# WKUP_CTRL_MMR0_WKUP_CTRL_MMR_CFG0_43000000h register map
Vendor: Texas Instruments
Registers are 32-bit, read-write, reset 0x0 unless marked. A register's access mark holds for its fields unless they carry their own. Offsets are as the file gives them; [hi:lo] are bit positions; {n}, {i} and the like mark numbered series.

## wkup_ctrl_mmr_CFG0 (part 2 of 3)
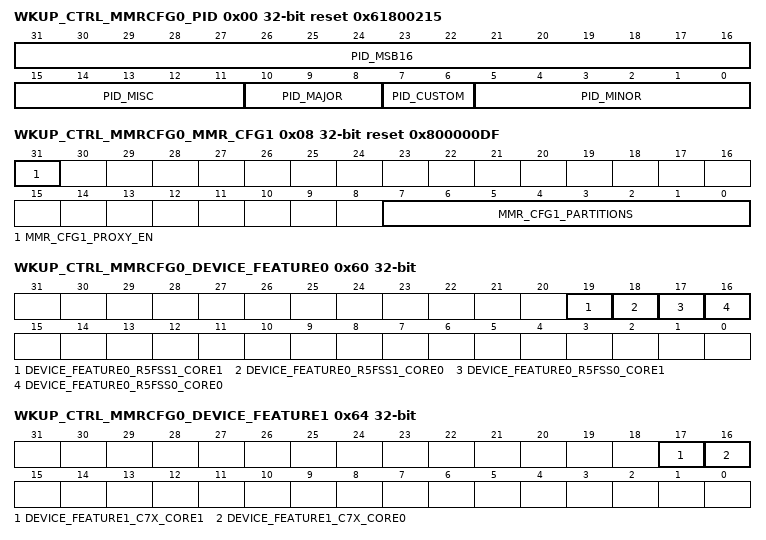
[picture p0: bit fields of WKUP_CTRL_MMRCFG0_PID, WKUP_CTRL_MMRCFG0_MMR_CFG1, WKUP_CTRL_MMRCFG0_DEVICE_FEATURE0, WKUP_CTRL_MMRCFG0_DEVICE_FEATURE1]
0x00 WKUP_CTRL_MMRCFG0_PID ro reset 0x61800215
  [31:16] PID_MSB16 — Reset Source: mod_g_rst_n
  [15:11] PID_MISC — Reset Source: mod_g_rst_n
  [10:8] PID_MAJOR — Reset Source: mod_g_rst_n
  [7:6] PID_CUSTOM — Reset Source: mod_g_rst_n
  [5:0] PID_MINOR — Reset Source: mod_g_rst_n
0x08 WKUP_CTRL_MMRCFG0_MMR_CFG1 ro reset 0x800000DF — Indicates the MMR configuration
  [31] MMR_CFG1_PROXY_EN — Proxy addressing enabled Reset Source: mod_por_rst_n
  [7:0] MMR_CFG1_PARTITIONS — Indicates present partitions Reset Source: mod_por_rst_n
0x44 WKUP_CTRL_MMRCFG0_BOOT_PROGRESS — Used by ROM to mark the progress of the boot operation
  [31:0] BOOT_PROGRESS_PROGRESS — Written by ROM to indicate boot progression. Values and their meaning are determined by the ROM. Reset Source: mod_por_rst_n
0x60 WKUP_CTRL_MMRCFG0_DEVICE_FEATURE0 ro — Indicates enabled Main Domain processing elements on the device
  [19] DEVICE_FEATURE0_R5FSS1_CORE1 — Main R5FSS1 dual/single core supportField values (others are reserved):1'b0 - Single core1'b1 - Dual core Reset Source: mod_por_rst_n
  [18] DEVICE_FEATURE0_R5FSS1_CORE0 — Main R5SS1 avalabilityField values (others are reserved):1'b0 - Cluster not available1'b1 - Cluster available Reset Source: mod_por_rst_n
  [17] DEVICE_FEATURE0_R5FSS0_CORE1 — Main R5FSS0 dual/single core supportField values (others are reserved):1'b0 - Single core1'b1 - Dual core Reset Source: mod_por_rst_n
  [16] DEVICE_FEATURE0_R5FSS0_CORE0 — Main R5SS0 avalabilityField values (others are reserved):1'b0 - Cluster not available1'b1 - Cluster available Reset Source: mod_por_rst_n
0x64 WKUP_CTRL_MMRCFG0_DEVICE_FEATURE1 ro — Indicates enabled Main Domain DSP processing elements on the device
  [17] DEVICE_FEATURE1_C7X_CORE1 — C7x1 AvailabilityField values (others are reserved):1'b0 - Not available1'b1 - Available Reset Source: mod_por_rst_n
  [16] DEVICE_FEATURE1_C7X_CORE0 — C7x0 AvailabilityField values (others are reserved):1'b0 - Not available1'b1 - Available Reset Source: mod_por_rst_n
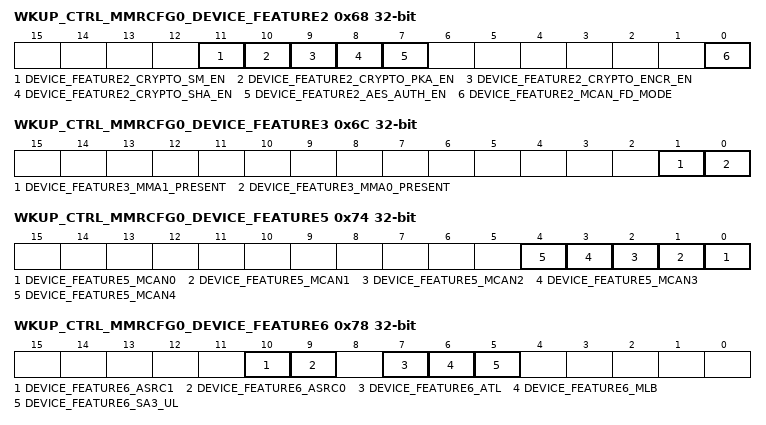
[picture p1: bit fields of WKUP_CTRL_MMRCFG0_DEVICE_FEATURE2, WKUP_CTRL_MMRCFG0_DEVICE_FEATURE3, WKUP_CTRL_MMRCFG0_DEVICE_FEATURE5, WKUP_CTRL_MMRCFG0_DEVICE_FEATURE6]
0x68 WKUP_CTRL_MMRCFG0_DEVICE_FEATURE2 ro — Indicates enabled interface elements on the device
  [11] DEVICE_FEATURE2_CRYPTO_SM_EN — Crypto Module SM2, SM3, SM4 AvailabilityField values (others are reserved):1'b0 - Not available1'b1 - Available Reset Source: mod_por_rst_n
  [10] DEVICE_FEATURE2_CRYPTO_PKA_EN — Crypto Module PKA AvailabilityField values (others are reserved):1'b0 - Not available1'b1 - Available Reset Source: mod_por_rst_n
  [9] DEVICE_FEATURE2_CRYPTO_ENCR_EN — Crypto Module AES/3DES/DBRG AvailabilityField values (others are reserved):1'b0 - Not available1'b1 - Available Reset Source: mod_por_rst_n
  [8] DEVICE_FEATURE2_CRYPTO_SHA_EN — Crypto Module SHA/MD5 AvailabilityField values (others are reserved):1'b0 - Not available1'b1 - Available Reset Source: mod_por_rst_n
  [7] DEVICE_FEATURE2_AES_AUTH_EN — AES authentication availability in FlashSS and SMSField values (others are reserved):1'b0 - Not available1'b1 - Available Reset Source: mod_por_rst_n
  [0] DEVICE_FEATURE2_MCAN_FD_MODE — FD mode availability (applies to all MCAN instances)Field values (others are reserved):1'b0 - Not available1'b1 - Available Reset Source: mod_por_rst_n
0x6C WKUP_CTRL_MMRCFG0_DEVICE_FEATURE3 ro — Indicates enabled processing element features on the device
  [1] DEVICE_FEATURE3_MMA1_PRESENT — C7x1 MMA Feature Availability Reset Source: mod_por_rst_n
  [0] DEVICE_FEATURE3_MMA0_PRESENT — C7x0 MMA Feature Availability Reset Source: mod_por_rst_n
0x74 WKUP_CTRL_MMRCFG0_DEVICE_FEATURE5 ro — Indicates enabled interface elements on the device
  [n] DEVICE_FEATURE5_MCAN{n} (n=0..4) — MCAN{n} AvailabilityField values (others are reserved):1'b0 - Not available1'b1 - Available Reset Source: mod_por_rst_n
0x78 WKUP_CTRL_MMRCFG0_DEVICE_FEATURE6 ro — Indicates enabled interface elements on the device
  [10] DEVICE_FEATURE6_ASRC1 — ASRC1 AvailabilityField values (others are reserved):1'b0 - Not available1'b1 - Available Reset Source: mod_por_rst_n
  [9] DEVICE_FEATURE6_ASRC0 — ASRC0 AvailabilityField values (others are reserved):1'b0 - Not available1'b1 - Available Reset Source: mod_por_rst_n
  [7] DEVICE_FEATURE6_ATL — Audio Tracking Logic AvailabilityField values (others are reserved):1'b0 - Not available1'b1 - Available Reset Source: mod_por_rst_n
  [6] DEVICE_FEATURE6_MLB — Medis Local Bus AvailabilityField values (others are reserved):1'b0 - Not available1'b1 - Available Reset Source: mod_por_rst_n
  [5] DEVICE_FEATURE6_SA3_UL — SA3SS domain security accelerator availabilityField values (others are reserved):1'b0 - Not available1'b1 - Available Reset Source: mod_por_rst_n
0x200 WKUP_CTRL_MMRCFG0_MAC_ID0 — Ethernet MAC address lower 32-bits
  [31:0] MAC_ID0_MACID_LO — 32 lsbs of MAC address Reset Source: mod_g_rst_n
0x204 WKUP_CTRL_MMRCFG0_MAC_ID1 — Ethernet MAC address upper 16-bits
  [15:0] MAC_ID1_MACID_HI — 16 msbs of MAC address Reset Source: mod_g_rst_n
0x220 WKUP_CTRL_MMRCFG0_USB_DEVICE_ID0 reset 0x61650451 — USB device and vendor ID register 0 (ROM Writes)
  [31:0] USB_DEVICE_ID0_ID0 — ROM writes 32-bit Value from Customer OTP to Here Reset Source: mod_g_rst_n
{0x230+4i} WKUP_CTRL_MMRCFG0_GP_SW{i} ro (i=0..2) — Allocated for customer use - Ex. Storage of PID/VID, Model #, Etc.
  [31:0] GP_SW{i}_VAL — general purpose value Reset Source: mod_por_rst_n
0x23C WKUP_CTRL_MMRCFG0_GP_SW3 ro — Allocated for customer use - Ex. Storage of PID/VID, Model #, Etc.
  [3:0] GP_SW3_VAL — general purpose value Reset Source: mod_por_rst_n
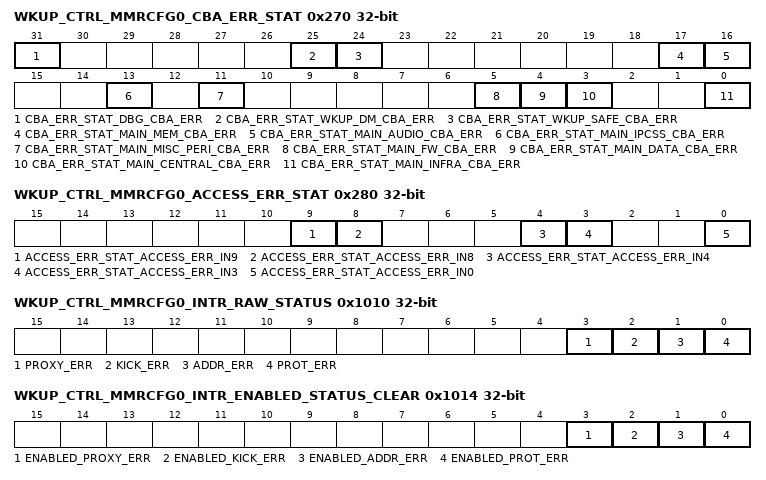
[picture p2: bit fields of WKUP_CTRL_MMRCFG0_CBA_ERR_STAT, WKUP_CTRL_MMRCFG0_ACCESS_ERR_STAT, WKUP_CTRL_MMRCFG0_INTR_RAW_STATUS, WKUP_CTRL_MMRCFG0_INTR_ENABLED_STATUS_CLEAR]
0x270 WKUP_CTRL_MMRCFG0_CBA_ERR_STAT ro — Provides Aggregated, Read Only status of bus address error interrupts reported by CBASS components.. Processors on the SoC read this MMR to determine which CBASS components require service. Actual service of CBASS interrupts must be handled through each CBASS component.
  [31] CBA_ERR_STAT_DBG_CBA_ERR — Access Error from Main Debug CBASSField values (others are reserved):1'b0 - INACTIVE1'b1 - ACTIVE Reset Source: mod_g_rst_n
  [25] CBA_ERR_STAT_WKUP_DM_CBA_ERR — Access Error from Wkup Device Manager CBASSField values (others are reserved):1'b0 - INACTIVE1'b1 - ACTIVE Reset Source: mod_g_rst_n
  [24] CBA_ERR_STAT_WKUP_SAFE_CBA_ERR — Access Error from Wkup Safe CBASSField values (others are reserved):1'b0 - INACTIVE1'b1 - ACTIVE Reset Source: mod_g_rst_n
  [17] CBA_ERR_STAT_MAIN_MEM_CBA_ERR — Access Error from Main MEM CBASS Reset Source: mod_g_rst_n
  [16] CBA_ERR_STAT_MAIN_AUDIO_CBA_ERR — Access Error from Main Audio CBASSField values (others are reserved):1'b0 - INACTIVE1'b1 - ACTIVE Reset Source: mod_g_rst_n
  [13] CBA_ERR_STAT_MAIN_IPCSS_CBA_ERR — Access Error from Main IPCSS CBASSField values (others are reserved):1'b0 - INACTIVE1'b1 - ACTIVE Reset Source: mod_g_rst_n
  [11] CBA_ERR_STAT_MAIN_MISC_PERI_CBA_ERR — Access Errror from Main Misc. Peripheral CBASSField values (others are reserved):1'b0 - INACTIVE1'b1 - ACTIVE Reset Source: mod_g_rst_n
  [5] CBA_ERR_STAT_MAIN_FW_CBA_ERR — Access Error from Main Firewall CBASSField values (others are reserved):1'b0 - INACTIVE1'b1 - ACTIVE Reset Source: mod_g_rst_n
  [4] CBA_ERR_STAT_MAIN_DATA_CBA_ERR — Access Error from Main Data CBASSField values (others are reserved):1'b0 - INACTIVE1'b1 - ACTIVE Reset Source: mod_g_rst_n
  [3] CBA_ERR_STAT_MAIN_CENTRAL_CBA_ERR — Access Error from Main Central CBASSField values (others are reserved):1'b0 - INACTIVE1'b1 - ACTIVE Reset Source: mod_g_rst_n
  [0] CBA_ERR_STAT_MAIN_INFRA_CBA_ERR — Access Error from Main Infrastructure CBASSField values (others are reserved):1'b0 - INACTIVE1'b1 - ACTIVE Reset Source: mod_g_rst_n
0x280 WKUP_CTRL_MMRCFG0_ACCESS_ERR_STAT ro — Provides Aggregated, Read Only status of access error interrupts reported by MMR components.. Processors on the SoC read this MMR to determine which MMR components require service. Actual service of MMR interrupts must be handled through each MMR component.
  [9] ACCESS_ERR_STAT_ACCESS_ERR_IN9 — Access Error Detected in MCU PadCfg MMRField values (others are reserved):1'b0 - INACTIVE1'b1 - ACTIVE Reset Source: mod_por_rst_n
  [8] ACCESS_ERR_STAT_ACCESS_ERR_IN8 — Access Error Detected in MCU Ctrl MMRField values (others are reserved):1'b0 - INACTIVE1'b1 - ACTIVE Reset Source: mod_por_rst_n
  [4] ACCESS_ERR_STAT_ACCESS_ERR_IN4 — Access Error Detected in MAIN PadCfg MMRField values (others are reserved):1'b0 - INACTIVE1'b1 - ACTIVE Reset Source: mod_por_rst_n
  [3] ACCESS_ERR_STAT_ACCESS_ERR_IN3 — Access Error Detected in MAIN Ctrl MMRField values (others are reserved):1'b0 - INACTIVE1'b1 - ACTIVE Reset Source: mod_por_rst_n
  [0] ACCESS_ERR_STAT_ACCESS_ERR_IN0 — Access Error Detected in WKUP Ctrl MMRField values (others are reserved):1'b0 - INACTIVE1'b1 - ACTIVE Reset Source: mod_por_rst_n
{0x1008+0x4000*i} WKUP_CTRL_MMRCFG0_LOCK{i}_KICK0 (i=0..3)
  [31:0] LOCK{i}_KICK0 — - KICK0 component Reset Source: mod_g_rst_n
{0x100C+0x4000*i} WKUP_CTRL_MMRCFG0_LOCK{i}_KICK1 (i=0..3)
  [31:0] LOCK{i}_KICK1 — - KICK1 component Reset Source: mod_g_rst_n
0x1010 WKUP_CTRL_MMRCFG0_INTR_RAW_STATUS access not given
  [3] PROXY_ERR — Proxy0 access violation error. Raw status is read. Write a 1 to set the status. Writing a 0 has no effect. Reset Source: mod_g_rst_n (access R/W1TS)
  [2] KICK_ERR — Kick access violation error. Raw status is read. Write a 1 to set the status. Writing a 0 has no effect. Reset Source: mod_g_rst_n (access R/W1TS)
  [1] ADDR_ERR — Addressing violation error. Raw status is read. Write a 1 to set the status. Writing a 0 has no effect. Reset Source: mod_g_rst_n (access R/W1TS)
  [0] PROT_ERR — Protection violation error. Raw status is read. Write a 1 to set the status. Writing a 0 has no effect. Reset Source: mod_g_rst_n (access R/W1TS)
0x1014 WKUP_CTRL_MMRCFG0_INTR_ENABLED_STATUS_CLEAR access not given
  [3] ENABLED_PROXY_ERR — Proxy0 access violation error. Enabled status is read. Write a 1 to clear the status. Writing a 0 has no effect. Reset Source: mod_g_rst_n (access R/W1TC)
  [2] ENABLED_KICK_ERR — Kick access violation error. Enabled status is read. Write a 1 to clear the status. Writing a 0 has no effect. Reset Source: mod_g_rst_n (access R/W1TC)
  [1] ENABLED_ADDR_ERR — Addressing violation error. Enabled status is read. Write a 1 to clear the status. Writing a 0 has no effect. Reset Source: mod_g_rst_n (access R/W1TC)
  [0] ENABLED_PROT_ERR — Protection violation error. Enabled status is read. Write a 1 to clear the status. Writing a 0 has no effect. Reset Source: mod_g_rst_n (access R/W1TC)
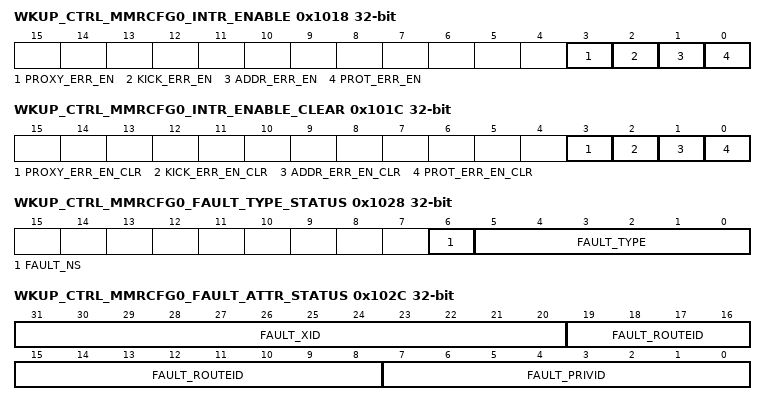
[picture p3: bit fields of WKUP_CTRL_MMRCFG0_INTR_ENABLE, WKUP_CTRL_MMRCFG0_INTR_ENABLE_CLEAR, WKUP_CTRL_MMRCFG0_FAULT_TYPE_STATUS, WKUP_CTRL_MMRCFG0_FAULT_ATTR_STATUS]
0x1018 WKUP_CTRL_MMRCFG0_INTR_ENABLE access not given
  [3] PROXY_ERR_EN — Proxy0 access violation error enable. Write a 1 to set the enable. Writing a 0 has no effect. Reset Source: mod_g_rst_n (access R/W1TS)
  [2] KICK_ERR_EN — Kick access violation error enable. Write a 1 to set the enable. Writing a 0 has no effect. Reset Source: mod_g_rst_n (access R/W1TS)
  [1] ADDR_ERR_EN — Addressing violation error enable. Write a 1 to set the enable. Writing a 0 has no effect. Reset Source: mod_g_rst_n (access R/W1TS)
  [0] PROT_ERR_EN — Protection violation error enable. Write a 1 to set the enable. Writing a 0 has no effect. Reset Source: mod_g_rst_n (access R/W1TS)
0x101C WKUP_CTRL_MMRCFG0_INTR_ENABLE_CLEAR access not given
  [3] PROXY_ERR_EN_CLR — Proxy0 access violation error enable clear. Write a 1 to clear the enable. Writing a 0 has no effect. Reset Source: mod_g_rst_n (access R/W1TC)
  [2] KICK_ERR_EN_CLR — Kick access violation error enable clear. Write a 1 to clear the enable. Writing a 0 has no effect. Reset Source: mod_g_rst_n (access R/W1TC)
  [1] ADDR_ERR_EN_CLR — Addressing violation error enable clear. Write a 1 to clear the enable. Writing a 0 has no effect. Reset Source: mod_g_rst_n (access R/W1TC)
  [0] PROT_ERR_EN_CLR — Protection violation error enable clear. Write a 1 to clear the enable. Writing a 0 has no effect. Reset Source: mod_g_rst_n (access R/W1TC)
0x1024 WKUP_CTRL_MMRCFG0_FAULT_ADDRESS ro
  [31:0] FAULT_ADDR — Fault Address. Reset Source: mod_g_rst_n
0x1028 WKUP_CTRL_MMRCFG0_FAULT_TYPE_STATUS ro
  [6] FAULT_NS — Non-secure access. Reset Source: mod_g_rst_n
  [5:0] FAULT_TYPE — Fault Type 10_0000 = Supervisor read fault - priv = 1 dir = 1 dtype != 1 01_0000 = Supervisor write fault - priv = 1 dir = 0 00_1000 = Supervisor execute fault - priv = 1 dir = 1 dtype = 1 00_0100 = User read fault - priv = 0 dir = 1 dtype = 1 00_0010 = User write fault - priv = 0 dir = 0 00_0001 = User execute fault - priv = 0 dir = 1 dtype = 1 00_0000 = No fault Reset Source: mod_g_rst_n
0x102C WKUP_CTRL_MMRCFG0_FAULT_ATTR_STATUS ro
  [31:20] FAULT_XID — XID. Reset Source: mod_g_rst_n
  [19:8] FAULT_ROUTEID — Route ID. Reset Source: mod_g_rst_n
  [7:0] FAULT_PRIVID — Privilege ID. Reset Source: mod_g_rst_n
0x1030 WKUP_CTRL_MMRCFG0_FAULT_CLEAR wo
  [0] FAULT_CLR — Fault clear. Writing a 1 clears the current fault. Writing a 0 has no effect. Reset Source: mod_g_rst_n
0x1100 WKUP_CTRL_MMRCFG0_CLAIMREG_P0_R0_READONLY ro
  [31:0] CLAIMREG_P0_R0_READONLY — Claim bits for Partition 0 Reset Source: mod_g_rst_n
0x1110 WKUP_CTRL_MMRCFG0_CLAIMREG_P0_R4_READONLY ro
  [31:0] CLAIMREG_P0_R4_READONLY — Claim bits for Partition 0 Reset Source: mod_g_rst_n
0x1114 WKUP_CTRL_MMRCFG0_CLAIMREG_P0_R5_READONLY ro
  [31:0] CLAIMREG_P0_R5_READONLY — Claim bits for Partition 0 Reset Source: mod_g_rst_n
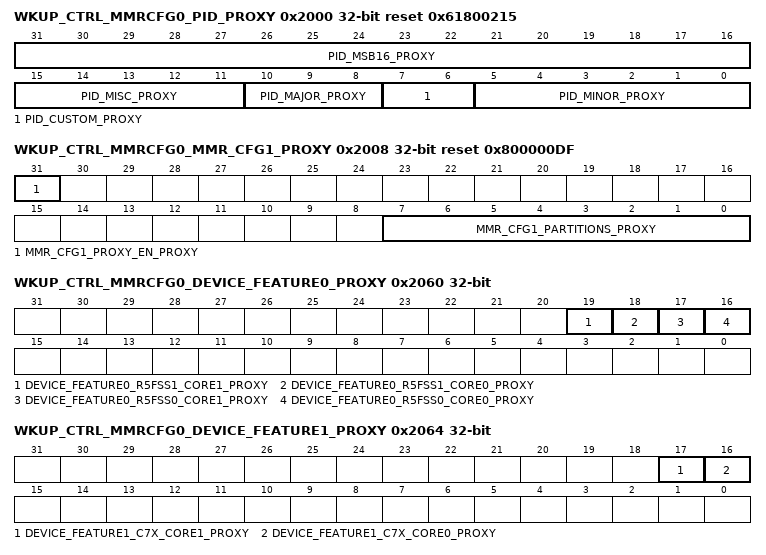
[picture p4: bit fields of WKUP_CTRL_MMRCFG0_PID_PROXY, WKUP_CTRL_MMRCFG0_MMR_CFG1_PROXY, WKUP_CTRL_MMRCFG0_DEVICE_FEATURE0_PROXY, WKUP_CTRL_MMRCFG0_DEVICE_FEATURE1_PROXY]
0x2000 WKUP_CTRL_MMRCFG0_PID_PROXY ro reset 0x61800215
  [31:16] PID_MSB16_PROXY — Reset Source: mod_g_rst_n
  [15:11] PID_MISC_PROXY — Reset Source: mod_g_rst_n
  [10:8] PID_MAJOR_PROXY — Reset Source: mod_g_rst_n
  [7:6] PID_CUSTOM_PROXY — Reset Source: mod_g_rst_n
  [5:0] PID_MINOR_PROXY — Reset Source: mod_g_rst_n
0x2008 WKUP_CTRL_MMRCFG0_MMR_CFG1_PROXY ro reset 0x800000DF — Indicates the MMR configuration
  [31] MMR_CFG1_PROXY_EN_PROXY — Proxy addressing enabled Reset Source: mod_por_rst_n
  [7:0] MMR_CFG1_PARTITIONS_PROXY — Indicates present partitions Reset Source: mod_por_rst_n
0x2044 WKUP_CTRL_MMRCFG0_BOOT_PROGRESS_PROXY — Used by ROM to mark the progress of the boot operation
  [31:0] BOOT_PROGRESS_PROGRESS_PROXY — Written by ROM to indicate boot progression. Values and their meaning are determined by the ROM. Reset Source: mod_por_rst_n
0x2060 WKUP_CTRL_MMRCFG0_DEVICE_FEATURE0_PROXY ro — Indicates enabled Main Domain processing elements on the device
  [19] DEVICE_FEATURE0_R5FSS1_CORE1_PROXY — Main R5FSS1 dual/single core supportField values (others are reserved):1'b0 - Single core1'b1 - Dual core Reset Source: mod_por_rst_n
  [18] DEVICE_FEATURE0_R5FSS1_CORE0_PROXY — Main R5SS1 avalabilityField values (others are reserved):1'b0 - Cluster not available1'b1 - Cluster available Reset Source: mod_por_rst_n
  [17] DEVICE_FEATURE0_R5FSS0_CORE1_PROXY — Main R5FSS0 dual/single core supportField values (others are reserved):1'b0 - Single core1'b1 - Dual core Reset Source: mod_por_rst_n
  [16] DEVICE_FEATURE0_R5FSS0_CORE0_PROXY — Main R5SS0 avalabilityField values (others are reserved):1'b0 - Cluster not available1'b1 - Cluster available Reset Source: mod_por_rst_n
0x2064 WKUP_CTRL_MMRCFG0_DEVICE_FEATURE1_PROXY ro — Indicates enabled Main Domain DSP processing elements on the device
  [17] DEVICE_FEATURE1_C7X_CORE1_PROXY — C7x1 AvailabilityField values (others are reserved):1'b0 - Not available1'b1 - Available Reset Source: mod_por_rst_n
  [16] DEVICE_FEATURE1_C7X_CORE0_PROXY — C7x0 AvailabilityField values (others are reserved):1'b0 - Not available1'b1 - Available Reset Source: mod_por_rst_n
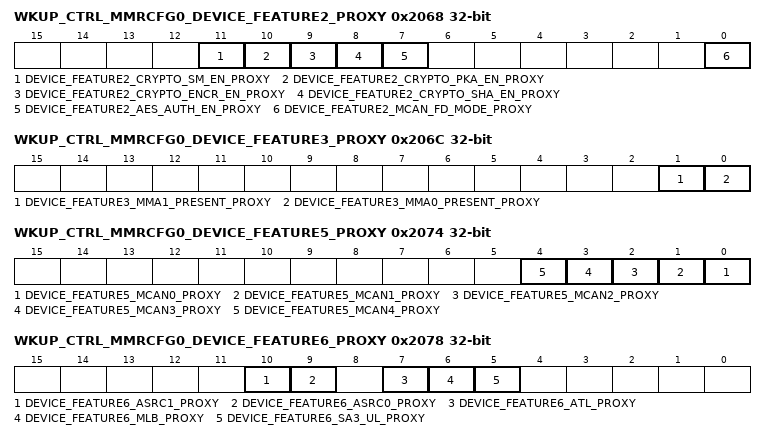
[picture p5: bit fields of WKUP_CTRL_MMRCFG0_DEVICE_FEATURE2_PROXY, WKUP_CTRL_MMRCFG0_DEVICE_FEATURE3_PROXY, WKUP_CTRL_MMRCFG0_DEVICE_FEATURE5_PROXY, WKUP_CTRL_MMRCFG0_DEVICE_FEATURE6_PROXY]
0x2068 WKUP_CTRL_MMRCFG0_DEVICE_FEATURE2_PROXY ro — Indicates enabled interface elements on the device
  [11] DEVICE_FEATURE2_CRYPTO_SM_EN_PROXY — Crypto Module SM2, SM3, SM4 AvailabilityField values (others are reserved):1'b0 - Not available1'b1 - Available Reset Source: mod_por_rst_n
  [10] DEVICE_FEATURE2_CRYPTO_PKA_EN_PROXY — Crypto Module PKA AvailabilityField values (others are reserved):1'b0 - Not available1'b1 - Available Reset Source: mod_por_rst_n
  [9] DEVICE_FEATURE2_CRYPTO_ENCR_EN_PROXY — Crypto Module AES/3DES/DBRG AvailabilityField values (others are reserved):1'b0 - Not available1'b1 - Available Reset Source: mod_por_rst_n
  [8] DEVICE_FEATURE2_CRYPTO_SHA_EN_PROXY — Crypto Module SHA/MD5 AvailabilityField values (others are reserved):1'b0 - Not available1'b1 - Available Reset Source: mod_por_rst_n
  [7] DEVICE_FEATURE2_AES_AUTH_EN_PROXY — AES authentication availability in FlashSS and SMSField values (others are reserved):1'b0 - Not available1'b1 - Available Reset Source: mod_por_rst_n
  [0] DEVICE_FEATURE2_MCAN_FD_MODE_PROXY — FD mode availability (applies to all MCAN instances)Field values (others are reserved):1'b0 - Not available1'b1 - Available Reset Source: mod_por_rst_n
0x206C WKUP_CTRL_MMRCFG0_DEVICE_FEATURE3_PROXY ro — Indicates enabled processing element features on the device
  [1] DEVICE_FEATURE3_MMA1_PRESENT_PROXY — C7x1 MMA Feature Availability Reset Source: mod_por_rst_n
  [0] DEVICE_FEATURE3_MMA0_PRESENT_PROXY — C7x0 MMA Feature Availability Reset Source: mod_por_rst_n
0x2074 WKUP_CTRL_MMRCFG0_DEVICE_FEATURE5_PROXY ro — Indicates enabled interface elements on the device
  [n] DEVICE_FEATURE5_MCAN{n}_PROXY (n=0..4) — MCAN{n} AvailabilityField values (others are reserved):1'b0 - Not available1'b1 - Available Reset Source: mod_por_rst_n
0x2078 WKUP_CTRL_MMRCFG0_DEVICE_FEATURE6_PROXY ro — Indicates enabled interface elements on the device
  [10] DEVICE_FEATURE6_ASRC1_PROXY — ASRC1 AvailabilityField values (others are reserved):1'b0 - Not available1'b1 - Available Reset Source: mod_por_rst_n
  [9] DEVICE_FEATURE6_ASRC0_PROXY — ASRC0 AvailabilityField values (others are reserved):1'b0 - Not available1'b1 - Available Reset Source: mod_por_rst_n
  [7] DEVICE_FEATURE6_ATL_PROXY — Audio Tracking Logic AvailabilityField values (others are reserved):1'b0 - Not available1'b1 - Available Reset Source: mod_por_rst_n
  [6] DEVICE_FEATURE6_MLB_PROXY — Medis Local Bus AvailabilityField values (others are reserved):1'b0 - Not available1'b1 - Available Reset Source: mod_por_rst_n
  [5] DEVICE_FEATURE6_SA3_UL_PROXY — SA3SS domain security accelerator availabilityField values (others are reserved):1'b0 - Not available1'b1 - Available Reset Source: mod_por_rst_n
0x2200 WKUP_CTRL_MMRCFG0_MAC_ID0_PROXY — Ethernet MAC address lower 32-bits
  [31:0] MAC_ID0_MACID_LO_PROXY — 32 lsbs of MAC address Reset Source: mod_g_rst_n
0x2204 WKUP_CTRL_MMRCFG0_MAC_ID1_PROXY — Ethernet MAC address upper 16-bits
  [15:0] MAC_ID1_MACID_HI_PROXY — 16 msbs of MAC address Reset Source: mod_g_rst_n
0x2220 WKUP_CTRL_MMRCFG0_USB_DEVICE_ID0_PROXY reset 0x61650451 — USB device and vendor ID register 0 (ROM Writes)
  [31:0] USB_DEVICE_ID0_ID0_PROXY — ROM writes 32-bit Value from Customer OTP to Here Reset Source: mod_g_rst_n
{0x2230+4i} WKUP_CTRL_MMRCFG0_GP_SW{i}_PROXY ro (i=0..2) — Allocated for customer use - Ex. Storage of PID/VID, Model #, Etc.
  [31:0] GP_SW{i}_VAL_PROXY — general purpose value Reset Source: mod_por_rst_n
0x223C WKUP_CTRL_MMRCFG0_GP_SW3_PROXY ro — Allocated for customer use - Ex. Storage of PID/VID, Model #, Etc.
  [3:0] GP_SW3_VAL_PROXY — general purpose value Reset Source: mod_por_rst_n
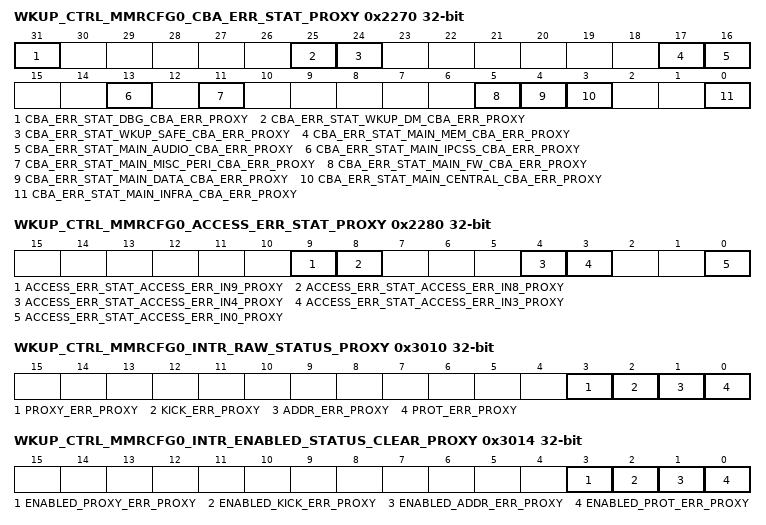
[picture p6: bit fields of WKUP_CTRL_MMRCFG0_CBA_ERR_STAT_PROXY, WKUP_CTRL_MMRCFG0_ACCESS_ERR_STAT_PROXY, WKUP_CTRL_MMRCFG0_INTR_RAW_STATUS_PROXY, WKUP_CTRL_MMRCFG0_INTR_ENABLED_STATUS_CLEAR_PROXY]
0x2270 WKUP_CTRL_MMRCFG0_CBA_ERR_STAT_PROXY ro — Provides Aggregated, Read Only status of bus address error interrupts reported by CBASS components.. Processors on the SoC read this MMR to determine which CBASS components require service. Actual service of CBASS interrupts must be handled through each CBASS component.
  [31] CBA_ERR_STAT_DBG_CBA_ERR_PROXY — Access Error from Main Debug CBASSField values (others are reserved):1'b0 - INACTIVE1'b1 - ACTIVE Reset Source: mod_g_rst_n
  [25] CBA_ERR_STAT_WKUP_DM_CBA_ERR_PROXY — Access Error from Wkup Device Manager CBASSField values (others are reserved):1'b0 - INACTIVE1'b1 - ACTIVE Reset Source: mod_g_rst_n
  [24] CBA_ERR_STAT_WKUP_SAFE_CBA_ERR_PROXY — Access Error from Wkup Safe CBASSField values (others are reserved):1'b0 - INACTIVE1'b1 - ACTIVE Reset Source: mod_g_rst_n
  [17] CBA_ERR_STAT_MAIN_MEM_CBA_ERR_PROXY — Access Error from Main MEM CBASS Reset Source: mod_g_rst_n
  [16] CBA_ERR_STAT_MAIN_AUDIO_CBA_ERR_PROXY — Access Error from Main Audio CBASSField values (others are reserved):1'b0 - INACTIVE1'b1 - ACTIVE Reset Source: mod_g_rst_n
  [13] CBA_ERR_STAT_MAIN_IPCSS_CBA_ERR_PROXY — Access Error from Main IPCSS CBASSField values (others are reserved):1'b0 - INACTIVE1'b1 - ACTIVE Reset Source: mod_g_rst_n
  [11] CBA_ERR_STAT_MAIN_MISC_PERI_CBA_ERR_PROXY — Access Errror from Main Misc. Peripheral CBASSField values (others are reserved):1'b0 - INACTIVE1'b1 - ACTIVE Reset Source: mod_g_rst_n
  [5] CBA_ERR_STAT_MAIN_FW_CBA_ERR_PROXY — Access Error from Main Firewall CBASSField values (others are reserved):1'b0 - INACTIVE1'b1 - ACTIVE Reset Source: mod_g_rst_n
  [4] CBA_ERR_STAT_MAIN_DATA_CBA_ERR_PROXY — Access Error from Main Data CBASSField values (others are reserved):1'b0 - INACTIVE1'b1 - ACTIVE Reset Source: mod_g_rst_n
  [3] CBA_ERR_STAT_MAIN_CENTRAL_CBA_ERR_PROXY — Access Error from Main Central CBASSField values (others are reserved):1'b0 - INACTIVE1'b1 - ACTIVE Reset Source: mod_g_rst_n
  [0] CBA_ERR_STAT_MAIN_INFRA_CBA_ERR_PROXY — Access Error from Main Infrastructure CBASSField values (others are reserved):1'b0 - INACTIVE1'b1 - ACTIVE Reset Source: mod_g_rst_n
0x2280 WKUP_CTRL_MMRCFG0_ACCESS_ERR_STAT_PROXY ro — Provides Aggregated, Read Only status of access error interrupts reported by MMR components.. Processors on the SoC read this MMR to determine which MMR components require service. Actual service of MMR interrupts must be handled through each MMR component.
  [9] ACCESS_ERR_STAT_ACCESS_ERR_IN9_PROXY — Access Error Detected in MCU PadCfg MMRField values (others are reserved):1'b0 - INACTIVE1'b1 - ACTIVE Reset Source: mod_por_rst_n
  [8] ACCESS_ERR_STAT_ACCESS_ERR_IN8_PROXY — Access Error Detected in MCU Ctrl MMRField values (others are reserved):1'b0 - INACTIVE1'b1 - ACTIVE Reset Source: mod_por_rst_n
  [4] ACCESS_ERR_STAT_ACCESS_ERR_IN4_PROXY — Access Error Detected in MAIN PadCfg MMRField values (others are reserved):1'b0 - INACTIVE1'b1 - ACTIVE Reset Source: mod_por_rst_n
  [3] ACCESS_ERR_STAT_ACCESS_ERR_IN3_PROXY — Access Error Detected in MAIN Ctrl MMRField values (others are reserved):1'b0 - INACTIVE1'b1 - ACTIVE Reset Source: mod_por_rst_n
  [0] ACCESS_ERR_STAT_ACCESS_ERR_IN0_PROXY — Access Error Detected in WKUP Ctrl MMRField values (others are reserved):1'b0 - INACTIVE1'b1 - ACTIVE Reset Source: mod_por_rst_n
{0x3008+0x4000*i} WKUP_CTRL_MMRCFG0_LOCK{i}_KICK0_PROXY (i=0..3)
  [31:0] LOCK{i}_KICK0_PROXY — - KICK0 component Reset Source: mod_g_rst_n
{0x300C+0x4000*i} WKUP_CTRL_MMRCFG0_LOCK{i}_KICK1_PROXY (i=0..3)
  [31:0] LOCK{i}_KICK1_PROXY — - KICK1 component Reset Source: mod_g_rst_n
0x3010 WKUP_CTRL_MMRCFG0_INTR_RAW_STATUS_PROXY access not given
  [3] PROXY_ERR_PROXY — Proxy0 access violation error. Raw status is read. Write a 1 to set the status. Writing a 0 has no effect. Reset Source: mod_g_rst_n (access R/W1TS)
  [2] KICK_ERR_PROXY — Kick access violation error. Raw status is read. Write a 1 to set the status. Writing a 0 has no effect. Reset Source: mod_g_rst_n (access R/W1TS)
  [1] ADDR_ERR_PROXY — Addressing violation error. Raw status is read. Write a 1 to set the status. Writing a 0 has no effect. Reset Source: mod_g_rst_n (access R/W1TS)
  [0] PROT_ERR_PROXY — Protection violation error. Raw status is read. Write a 1 to set the status. Writing a 0 has no effect. Reset Source: mod_g_rst_n (access R/W1TS)
0x3014 WKUP_CTRL_MMRCFG0_INTR_ENABLED_STATUS_CLEAR_PROXY access not given
  [3] ENABLED_PROXY_ERR_PROXY — Proxy0 access violation error. Enabled status is read. Write a 1 to clear the status. Writing a 0 has no effect. Reset Source: mod_g_rst_n (access R/W1TC)
  [2] ENABLED_KICK_ERR_PROXY — Kick access violation error. Enabled status is read. Write a 1 to clear the status. Writing a 0 has no effect. Reset Source: mod_g_rst_n (access R/W1TC)
  [1] ENABLED_ADDR_ERR_PROXY — Addressing violation error. Enabled status is read. Write a 1 to clear the status. Writing a 0 has no effect. Reset Source: mod_g_rst_n (access R/W1TC)
  [0] ENABLED_PROT_ERR_PROXY — Protection violation error. Enabled status is read. Write a 1 to clear the status. Writing a 0 has no effect. Reset Source: mod_g_rst_n (access R/W1TC)
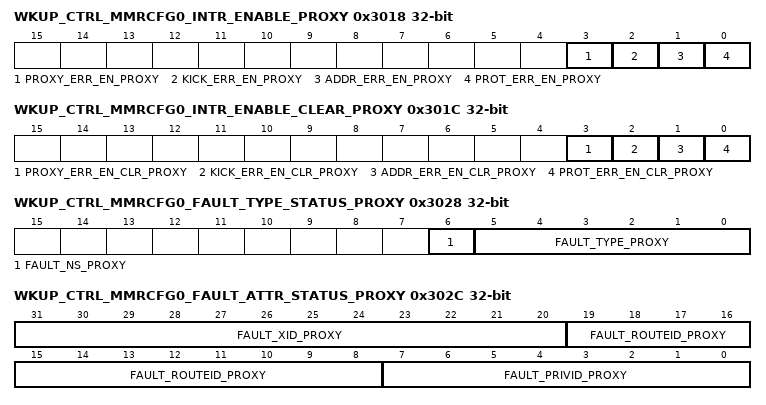
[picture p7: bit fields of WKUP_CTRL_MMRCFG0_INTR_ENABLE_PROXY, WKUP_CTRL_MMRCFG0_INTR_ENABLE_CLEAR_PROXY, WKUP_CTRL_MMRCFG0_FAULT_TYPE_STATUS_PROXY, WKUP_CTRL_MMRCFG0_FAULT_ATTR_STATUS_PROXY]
0x3018 WKUP_CTRL_MMRCFG0_INTR_ENABLE_PROXY access not given
  [3] PROXY_ERR_EN_PROXY — Proxy0 access violation error enable. Write a 1 to set the enable. Writing a 0 has no effect. Reset Source: mod_g_rst_n (access R/W1TS)
  [2] KICK_ERR_EN_PROXY — Kick access violation error enable. Write a 1 to set the enable. Writing a 0 has no effect. Reset Source: mod_g_rst_n (access R/W1TS)
  [1] ADDR_ERR_EN_PROXY — Addressing violation error enable. Write a 1 to set the enable. Writing a 0 has no effect. Reset Source: mod_g_rst_n (access R/W1TS)
  [0] PROT_ERR_EN_PROXY — Protection violation error enable. Write a 1 to set the enable. Writing a 0 has no effect. Reset Source: mod_g_rst_n (access R/W1TS)
0x301C WKUP_CTRL_MMRCFG0_INTR_ENABLE_CLEAR_PROXY access not given
  [3] PROXY_ERR_EN_CLR_PROXY — Proxy0 access violation error enable clear. Write a 1 to clear the enable. Writing a 0 has no effect. Reset Source: mod_g_rst_n (access R/W1TC)
  [2] KICK_ERR_EN_CLR_PROXY — Kick access violation error enable clear. Write a 1 to clear the enable. Writing a 0 has no effect. Reset Source: mod_g_rst_n (access R/W1TC)
  [1] ADDR_ERR_EN_CLR_PROXY — Addressing violation error enable clear. Write a 1 to clear the enable. Writing a 0 has no effect. Reset Source: mod_g_rst_n (access R/W1TC)
  [0] PROT_ERR_EN_CLR_PROXY — Protection violation error enable clear. Write a 1 to clear the enable. Writing a 0 has no effect. Reset Source: mod_g_rst_n (access R/W1TC)
0x3024 WKUP_CTRL_MMRCFG0_FAULT_ADDRESS_PROXY ro
  [31:0] FAULT_ADDR_PROXY — Fault Address. Reset Source: mod_g_rst_n
0x3028 WKUP_CTRL_MMRCFG0_FAULT_TYPE_STATUS_PROXY ro
  [6] FAULT_NS_PROXY — Non-secure access. Reset Source: mod_g_rst_n
  [5:0] FAULT_TYPE_PROXY — Fault Type 10_0000 = Supervisor read fault - priv = 1 dir = 1 dtype != 1 01_0000 = Supervisor write fault - priv = 1 dir = 0 00_1000 = Supervisor execute fault - priv = 1 dir = 1 dtype = 1 00_0100 = User read fault - priv = 0 dir = 1 dtype = 1 00_0010 = User write fault - priv = 0 dir = 0 00_0001 = User execute fault - priv = 0 dir = 1 dtype = 1 00_0000 = No fault Reset Source: mod_g_rst_n
0x302C WKUP_CTRL_MMRCFG0_FAULT_ATTR_STATUS_PROXY ro
  [31:20] FAULT_XID_PROXY — XID. Reset Source: mod_g_rst_n
  [19:8] FAULT_ROUTEID_PROXY — Route ID. Reset Source: mod_g_rst_n
  [7:0] FAULT_PRIVID_PROXY — Privilege ID. Reset Source: mod_g_rst_n
0x3030 WKUP_CTRL_MMRCFG0_FAULT_CLEAR_PROXY wo
  [0] FAULT_CLR_PROXY — Fault clear. Writing a 1 clears the current fault. Writing a 0 has no effect. Reset Source: mod_g_rst_n
{0x3100+4i} WKUP_CTRL_MMRCFG0_CLAIMREG_P0_R{i} (i=0..6)
  [31:0] CLAIMREG_P0_R{i} — Claim bits for Partition 0 Reset Source: mod_g_rst_n
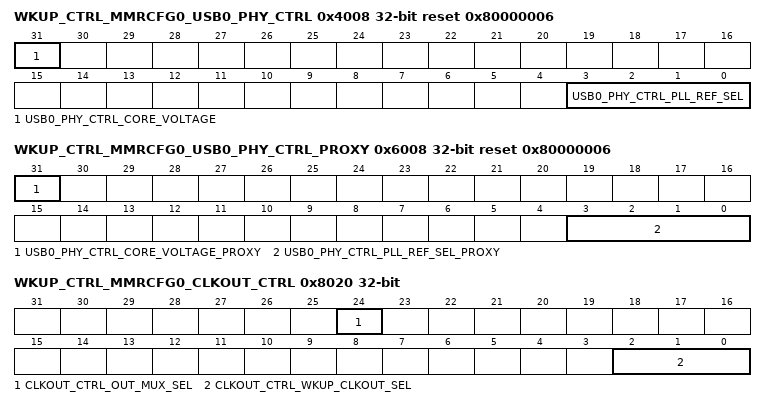
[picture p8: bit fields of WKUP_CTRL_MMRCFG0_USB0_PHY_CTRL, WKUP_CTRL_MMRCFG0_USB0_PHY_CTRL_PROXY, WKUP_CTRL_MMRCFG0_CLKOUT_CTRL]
0x4008 WKUP_CTRL_MMRCFG0_USB0_PHY_CTRL reset 0x80000006 — Configures the USB0 Phy operation
  [31] USB0_PHY_CTRL_CORE_VOLTAGE — Selects the USB PHY Core Voltage Option: 0.85V or 0.75/0.80VField values (others are reserved):1'b0 - V_0P851'b1 - V_0P75_0P80 Reset Source: mod_g_rst_n
  [3:0] USB0_PHY_CTRL_PLL_REF_SEL — Indicates the frequency of the REF_CLOCK input used by the USB PLL. This value should be set to match the frequency of the USB0 input clock, as selected by the USB0_CLKSEL registerField values (others are reserved):4'b0000 - MHZ_9P64'b0001 - MHZ_104'b0010 - MHZ_124'b0011 - MHZ_19P24'b0100 - MHZ_204'b0101 - MHZ_244'b0110 - MHZ_254'b0111 - MHZ_264'b1000 - MHZ_38P44'b1001 - MHZ_404'b1010 - MHZ_484'b1011 - MHZ_504'b1100 - MHZ_52 Reset Source: mod_g_rst_n
0x41B4 WKUP_CTRL_MMRCFG0_SDIO0_CTRL — Controls drive strength of MMC0 SDIO mode pins
  [4:0] SDIO0_CTRL_DRV_STR — Selects the SDIO pin drive strength. The default value trims the buffers for ~40 ohms. For options other than the Reset/Default 40 ohm, the register value should be modified as follows: 40 ohms - Default Value 33 ohms - Default Value + 5 50 ohms - Default Value -5 66 ohms - Default Value -10Note: Values other than the reset value may invalidate the datasheet timing parameters and therefore should not be used. Reset Source: mod_por_rst_n
0x4204 WKUP_CTRL_MMRCFG0_WKUP_TIMER1_CTRL — Controls TIMER1 operation
  [8] WKUP_TIMER1_CTRL_CASCADE_EN — Enables cascading of TIMER1 to TIMER0Field values (others are reserved):1'b0 - CASCADE_DISABLED1'b1 - CASCADE_ENABLED Reset Source: sys_por_rst_n
0x42E0 WKUP_CTRL_MMRCFG0_WKUP_I2C0_CTRL — Controls I2C0 operation for open drain I/Os
  [0] WKUP_I2C0_CTRL_HS_MCS_EN — HS Mode controller current source enable.When set, enables the current-source pull-up on the SCL output. Only one controller on the I2C bus should enable SCL current sourcing. Field values (others are reserved):1'b0 - HS_MCS_INACTIVE1'b1 - HS_MCS_ACTIVE Reset Source: mod_g_rst_n
0x5100 WKUP_CTRL_MMRCFG0_CLAIMREG_P1_R0_READONLY ro
  [31:0] CLAIMREG_P1_R0_READONLY — Claim bits for Partition 1 Reset Source: mod_g_rst_n
{0x5100+4i} WKUP_CTRL_MMRCFG0_CLAIMREG_P1_R{i}_READONLY ro (i=3..5)
  [31:0] CLAIMREG_P1_R{i}_READONLY — Claim bits for Partition 1 Reset Source: mod_g_rst_n
0x5130 WKUP_CTRL_MMRCFG0_CLAIMREG_P1_R12_READONLY ro
  [31:0] CLAIMREG_P1_R12_READONLY — Claim bits for Partition 1 Reset Source: mod_g_rst_n
0x6008 WKUP_CTRL_MMRCFG0_USB0_PHY_CTRL_PROXY reset 0x80000006 — Configures the USB0 Phy operation
  [31] USB0_PHY_CTRL_CORE_VOLTAGE_PROXY — Selects the USB PHY Core Voltage Option: 0.85V or 0.75/0.80VField values (others are reserved):1'b0 - V_0P851'b1 - V_0P75_0P80 Reset Source: mod_g_rst_n
  [3:0] USB0_PHY_CTRL_PLL_REF_SEL_PROXY — Indicates the frequency of the REF_CLOCK input used by the USB PLL. This value should be set to match the frequency of the USB0 input clock, as selected by the USB0_CLKSEL registerField values (others are reserved):4'b0000 - MHZ_9P64'b0001 - MHZ_104'b0010 - MHZ_124'b0011 - MHZ_19P24'b0100 - MHZ_204'b0101 - MHZ_244'b0110 - MHZ_254'b0111 - MHZ_264'b1000 - MHZ_38P44'b1001 - MHZ_404'b1010 - MHZ_484'b1011 - MHZ_504'b1100 - MHZ_52 Reset Source: mod_g_rst_n
0x61B4 WKUP_CTRL_MMRCFG0_SDIO0_CTRL_PROXY — Controls drive strength of MMC0 SDIO mode pins
  [4:0] SDIO0_CTRL_DRV_STR_PROXY — Selects the SDIO pin drive strength. The default value trims the buffers for ~40 ohms. For options other than the Reset/Default 40 ohm, the register value should be modified as follows: 40 ohms - Default Value 33 ohms - Default Value + 5 50 ohms - Default Value -5 66 ohms - Default Value -10Note: Values other than the reset value may invalidate the datasheet timing parameters and therefore should not be used. Reset Source: mod_por_rst_n
0x6204 WKUP_CTRL_MMRCFG0_WKUP_TIMER1_CTRL_PROXY — Controls TIMER1 operation
  [8] WKUP_TIMER1_CTRL_CASCADE_EN_PROXY — Enables cascading of TIMER1 to TIMER0Field values (others are reserved):1'b0 - CASCADE_DISABLED1'b1 - CASCADE_ENABLED Reset Source: sys_por_rst_n
0x62E0 WKUP_CTRL_MMRCFG0_WKUP_I2C0_CTRL_PROXY — Controls I2C0 operation for open drain I/Os
  [0] WKUP_I2C0_CTRL_HS_MCS_EN_PROXY — HS Mode controller current source enable.When set, enables the current-source pull-up on the SCL output. Only one controller on the I2C bus should enable SCL current sourcing. Field values (others are reserved):1'b0 - HS_MCS_INACTIVE1'b1 - HS_MCS_ACTIVE Reset Source: mod_g_rst_n
{0x7100+4i} WKUP_CTRL_MMRCFG0_CLAIMREG_P1_R{i} (i=0..12)
  [31:0] CLAIMREG_P1_R{i} — Claim bits for Partition 1 Reset Source: mod_g_rst_n
0x8010 WKUP_CTRL_MMRCFG0_WKUP_CLKSEL — Selects the functional clock source for the WKUP Domain
  [0] WKUP_CLKSEL_CLK_SEL — Selects Clock Source for Wakeup Domain (Device Manager and Peripherals)Field values (others are reserved):1'b0 - CPU_MAIN_PLL15_HSDIV2_CLKOUT__PERIPHERALS_ MAIN_PLL15_HSDIV0_CLKOUT1'b0 - MAIN_PLL15_HSDIV0_CLKOUT0 (HSM_DM_CLK)1'b1 - CPU_AND_PERIPHERALS_MCU_PLL0_HSDIV0_CLKOUT1'b1 - MCU_PLL0_HSDIV0_CKLOUT (MCU_SYSCLK0) Reset Source: mod_g_rst_n
0x8020 WKUP_CTRL_MMRCFG0_CLKOUT_CTRL — Enables and selects clock source of WKUP_CLKOUT pin
  [24] CLKOUT_CTRL_OUT_MUX_SEL — WKUP CLKOUT (Pin) pin output mux selection. HFOSC0_CLK is a direct output from the HFOSC0Field values (others are reserved):1'b0 - CLK_DIV_OUT1'b1 - HFOSC0_CLK (clk_sel must be DRIVE_LOW) Reset Source: mod_por_rst_n
  [2:0] CLKOUT_CTRL_WKUP_CLKOUT_SEL — Controls WKUP CLKOUT MUX for WKUP_CLKOUT0 PinField values (others are reserved):3'b000 - HFOSC0_CLKOUT_SERDES3'b000 - DRIVE_LOW3'b001 - LFOSC0_CLKOUT3'b010 - MAIN_PLL0_HSDIV2_CLKOUT3'b011 - MAIN_PLL1_HSDIV2_CLKOUT3'b100 - MAIN_PLL2_HSDIV9_CLKOUT3'b101 - DEVICE_CLKOUT_32K3'b110 - CLK_12M_RC3'b111 - HFOSC0_CLKOUT Reset Source: mod_por_rst_n
0x8030 WKUP_CTRL_MMRCFG0_WKUP_GTC_CLKSEL reset 0x1 — Selects the timebase clock source for the Global Timebase Counter
  [2:0] WKUP_GTC_CLKSEL_CLK_SEL — Selects the GTC timebase clock sourceField values (others are reserved):3'b000 - MAIN_PLL2_HSDIV5_CLKOUT3'b001 - MAIN_PLL0_HSDIV6_CLKOUT3'b010 - CP_GEMAC_CPTS0_RFT_CLK (Pin)3'b011 - Reserved '0'3'b100 - MCU_EXT_REFCLK0 (Pin)3'b101 - EXT_REFCLK1 (Pin)3'b110 - MCU_SYSCLK0_DIV23'b110 - MCU_SYSCLK0/23'b111 - MAIN_SYSCLK0 Reset Source: mod_g_rst_n
0x8190 WKUP_CTRL_MMRCFG0_USB0_CLKSEL — Selects the functional clock sources for USB0
  [0] USB0_CLKSEL_REFCLK_SEL — Selects the clock source for the USB0 ref_clk. Field values (others are reserved):1'b0 - HFOSC0_CLKOUT1'b1 - MAIN_PLL0_HSDIV8_CLKOUT Reset Source: mod_g_rst_n
0x81B0 WKUP_CTRL_MMRCFG0_WKUP_TIMER0_CLKSEL — Timer0 functional clock selection control
  [2:0] WKUP_TIMER0_CLKSEL_CLK_SEL — Timer functional clock input select mux controlField values (others are reserved):3'b000 - HFOSC0_CLKOUT3'b001 - DM_CLK/23'b001 - DM_CLK/43'b010 - CLK_12M_RC3'b011 - MCU_PLL0_HSDIV5_CLKOUT3'b100 - MCU_EXT_REFCLK0 (Pin)3'b101 - DEVICE_CLKOUT_32K3'b110 - CPSW0_CPTS_GENF03'b111 - CLK_32K_RC Reset Source: sys_por_rst_n
0x81B4 WKUP_CTRL_MMRCFG0_WKUP_TIMER1_CLKSEL — Timer1 functional clock selection control
  [2:0] WKUP_TIMER1_CLKSEL_CLK_SEL — Timer functional clock input select mux controlField values (others are reserved):3'b000 - HFOSC0_CLKOUT3'b001 - DM_CLK/23'b001 - DM_CLK/43'b010 - CLK_12M_RC3'b011 - MCU_PLL0_HSDIV5_CLKOUT3'b100 - MCU_EXT_REFCLK0 (Pin)3'b101 - DEVICE_CLKOUT_32K3'b110 - CPSW0_CPTS_GENF03'b111 - CLK_32K_RC Reset Source: sys_por_rst_n
